# HSM_HSM_DTHE_CE000000h register map
Vendor: Texas Instruments
Peripheral module from a debugger description file (folder AM261x).
Registers are 32-bit, read-only, reset 0x0 unless marked. A register's access mark holds for its fields unless they carry their own. Offsets are as the file gives them; lines under a group give offsets from that group; [hi:lo] are bit positions; {n}, {i} and the like mark numbered series; 'fields as' and 'values as' point back to an identical list; <NAME> marks a mode.

## HSM_DTHE
0x00 HSM_DTHE_S_EIP_CONFIG 8-bit rw — This register is used for secured request configuration.
  [1:0] CONFIG — This register is secured request configuration.Writing 3 to this register enables the mreqsecure to enable the write to S_SYSCONFIG register in AES and SHA.
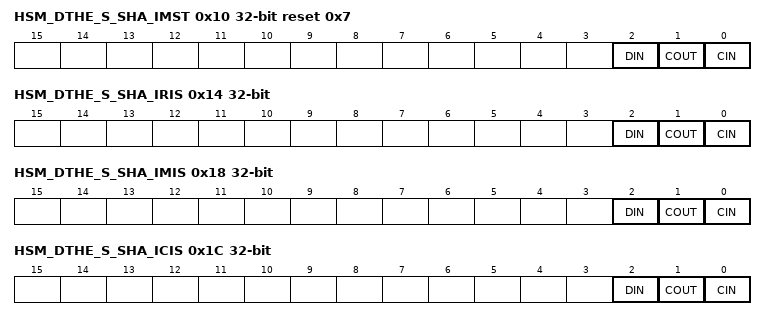
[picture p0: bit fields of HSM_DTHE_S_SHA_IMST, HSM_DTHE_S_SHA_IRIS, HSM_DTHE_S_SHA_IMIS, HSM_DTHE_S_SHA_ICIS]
0x10 HSM_DTHE_S_SHA_IMST rw reset 0x7 — Secured SHA Interrupt Mask Set Register.
  [2] DIN — Data in: this interrupt is raised when DMA writes last word of input data to internal FIFO of the engine
  [1] COUT — Context out: this interrupt is raised when DMA complets the output context movement from internal register
  [0] CIN — context in: this interrupt is raised when DMA complets Context write to internal register
0x14 HSM_DTHE_S_SHA_IRIS — Secured SHA Interrupt Raw Interrupt Status Register.
  [2] DIN — Input Data movement is done
  [1] COUT — Context output is done
  [0] CIN — context input is done
0x18 HSM_DTHE_S_SHA_IMIS — Secured SHA Interrupt Masked interrupt Status Registe.
  fields as HSM_DTHE_S_SHA_IRIS
0x1C HSM_DTHE_S_SHA_ICIS wo — Secured SHA Interrupt Clear Interrupt Status Register.
  [2] DIN — Clear'input Data movement done' flag
  [1] COUT — Clear'Context output done' flag
  [0] CIN — Clear'context input done' flag
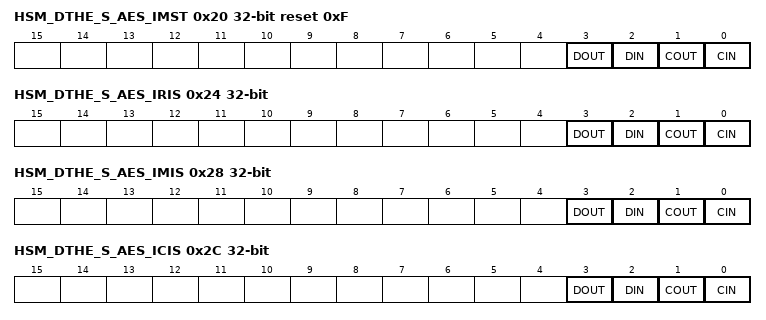
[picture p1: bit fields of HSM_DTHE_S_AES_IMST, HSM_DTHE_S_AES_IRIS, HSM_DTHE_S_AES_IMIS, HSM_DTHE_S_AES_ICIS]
0x20 HSM_DTHE_S_AES_IMST rw reset 0xF — Secured AES Interrupt Mask Set Register.
  [3] DOUT — Data out: this interrupt is raised when DMA finishes Writing last word of the process result
  [2] DIN — Data in: this interrupt is raised when DMA writes last word of input data to internal FIFO of the engine
  [1] COUT — Context out: this interrupt is raised when DMA complets the output context movement from internal register
  [0] CIN — context in: this interrupt is raised when DMA complets Context write to internal register
0x24 HSM_DTHE_S_AES_IRIS — Secured AES Interrupt Raw Interrupt Status Register.
  [3] DOUT — Output Data movement is done
  [2] DIN — Input Data movement is done
  [1] COUT — Context output is done
  [0] CIN — context input is done
0x28 HSM_DTHE_S_AES_IMIS — Secured AES Interrupt Masked interrupt Status Register.
  fields as HSM_DTHE_S_AES_IRIS
0x2C HSM_DTHE_S_AES_ICIS wo — Secured AES Interrupt Clear Interrupt Status Register.
  [3] DOUT — Clear'output Data movement done' flag
  [2] DIN — Clear'input Data movement done' flag
  [1] COUT — Clear'Context output done' flag
  [0] CIN — Clear'context input done' flag
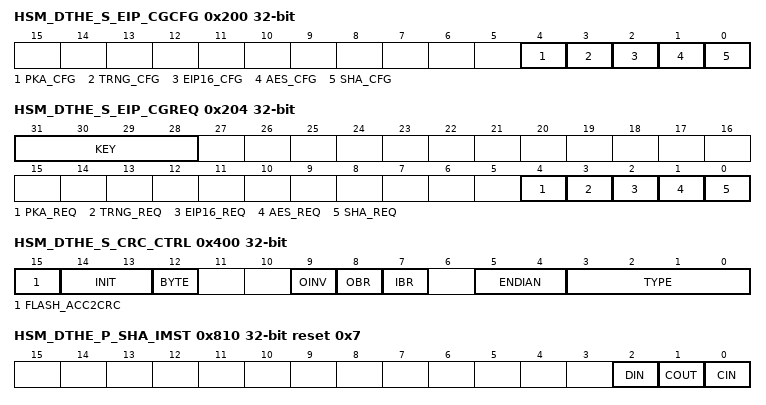
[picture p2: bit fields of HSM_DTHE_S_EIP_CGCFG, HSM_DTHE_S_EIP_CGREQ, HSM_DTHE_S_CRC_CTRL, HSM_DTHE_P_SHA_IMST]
0x200 HSM_DTHE_S_EIP_CGCFG wo — Secured EIP Clock gating configuration.
  [4] PKA_CFG — 0- request to un-gate 1- request to gate the clock.
  [3] TRNG_CFG — 0- request to un-gate 1- request to gate the clock.
  [2] EIP16_CFG — 0- request to un-gate 1- request to gate the clock.
  [1] AES_CFG — 0- request to un-gate 1- request to gate the clock.
  [0] SHA_CFG — 0- request to un-gate 1- request to gate the clock.
0x204 HSM_DTHE_S_EIP_CGREQ wo — Secured EIP Clock gating Request.
  [31:28] KEY — When'0x5' write'1' to lower bits [4:0] will set the bit. Write'0' will be ignoredWhen'0x2' write'1' to lower bit [4:0] will clear the bit. Write'0' will be ignoredfor other key value, regular read write operation
  [4] PKA_REQ — 0- request to un-gate 1- request to gate the clock.
  [3] TRNG_REQ — 0- request to un-gate 1- request to gate the clock.
  [2] EIP16_REQ — 0- request to un-gate 1- request to gate the clock.
  [1] AES_REQ — 0- request to un-gate 1- request to gate the clock.
  [0] SHA_REQ — 0- request to un-gate 1- request to gate the clock.
0x400 HSM_DTHE_S_CRC_CTRL rw — Secured CRC Control register.
  [15] FLASH_ACC2CRC — 1 if use Flash access port to feed CRC [uses length and address in that block to control data [Reserved]. Only present in DTHE_S_CRC_CTRL register
  [14:13] INIT — Initialize the CRC 00- use SEED register context as starting value 10- all'zero' 11- all'one' This is self clearing. With first write to data register this value clears to zero and remain zero for rest of the operation unless written again
  [12] BYTE — Input data size 0- 32 bit 1- 8 bit
  [9] OINV — Inverse the bits of result before storing to CRC_RSLT_PP0
  [8] OBR — Bit reserved the output result byte before storing to CRC_RSLT_PP0. applicable for all bytes in word
  [7] IBR — Bit reverse the input byte. For all bytes in word
  [5:4] ENDIAN — Endian control [0]- swap byte in half-word [1]- swap half word
  [3:0] TYPE — Type of operation0000 polynomial 0x8005 0001 polynomial 0x10210010 polynomial 0x4C11DB7 0011 polynomial 0x1EDC6F411000 TCP checksumTYPE in DTHE_S_CRC_CTRL & DTHE_S_CRC_CTRL should be exclusive
0x410 HSM_DTHE_S_CRC_SEED rw — SecuredCRC SEED/Context-CRC register.
  [31:0] SEED — Starting seed of CRC and checksum operation. Please see CTRL register for more detail. This resister also holds the latest result of CRC or checksum operation
0x414 HSM_DTHE_S_CRC_DIN rw — Secured CRC DATA Input register.
  [31:0] DATA_IN — Input data for CRC or checksum operation
0x418 HSM_DTHE_S_CRC_RSLT_PP — Secured CRC post processed output.
  [31:0] RSLT_PP — Result data of CRC or checksum operation
0x810 HSM_DTHE_P_SHA_IMST rw reset 0x7 — Public SHA Interrupt Mask Set Register.
  fields as HSM_DTHE_S_SHA_IMST
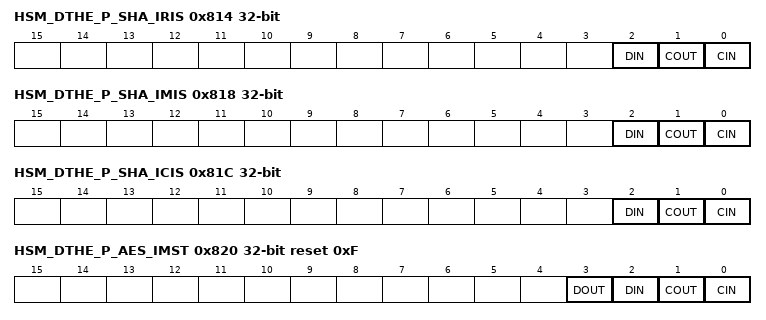
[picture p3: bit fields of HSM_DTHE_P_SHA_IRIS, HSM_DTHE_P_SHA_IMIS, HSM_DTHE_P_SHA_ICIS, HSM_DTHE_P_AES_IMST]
0x814 HSM_DTHE_P_SHA_IRIS — Public SHA Interrupt Raw Interrupt Status Register.
  fields as HSM_DTHE_S_SHA_IRIS
0x818 HSM_DTHE_P_SHA_IMIS — Public SHA Interrupt Masked interrupt Status Registe.
  fields as HSM_DTHE_S_SHA_IRIS
0x81C HSM_DTHE_P_SHA_ICIS wo — Public SHA Interrupt Clear Interrupt Status Register.
  fields as HSM_DTHE_S_SHA_ICIS
0x820 HSM_DTHE_P_AES_IMST rw reset 0xF — Public AES Interrupt Mask Set Register.
  fields as HSM_DTHE_S_AES_IMST
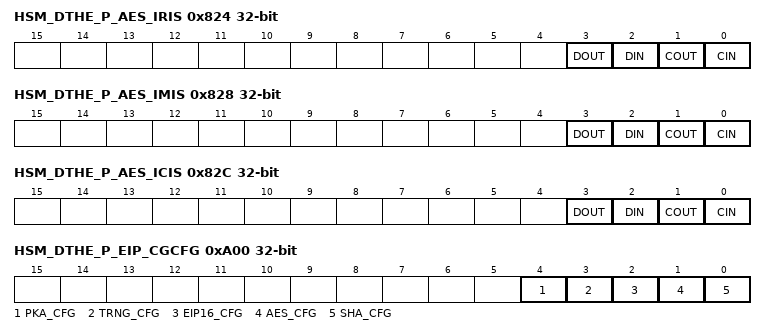
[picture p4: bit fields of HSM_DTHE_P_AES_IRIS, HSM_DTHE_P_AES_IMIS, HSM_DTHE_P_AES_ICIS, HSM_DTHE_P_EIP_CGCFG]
0x824 HSM_DTHE_P_AES_IRIS — Public AES Interrupt Raw Interrupt Status Register.
  fields as HSM_DTHE_S_AES_IRIS
0x828 HSM_DTHE_P_AES_IMIS — Public AES Interrupt Masked interrupt Status Register.
  fields as HSM_DTHE_S_AES_IRIS
0x82C HSM_DTHE_P_AES_ICIS access per field — Public AES Interrupt Clear Interrupt Status Register.
  [3] DOUT rw — Clear'output Data movement done' flag
  [2] DIN wo — Clear'input Data movement done' flag
  [1] COUT wo — Clear'Context output done' flag
  [0] CIN wo — Clear'context input done' flag
0xA00 HSM_DTHE_P_EIP_CGCFG wo — Public EIP Clock gating configuration.
  fields as HSM_DTHE_S_EIP_CGCFG
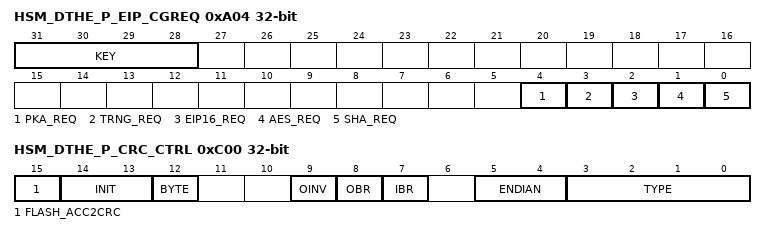
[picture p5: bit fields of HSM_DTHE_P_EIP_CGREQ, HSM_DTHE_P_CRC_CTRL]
0xA04 HSM_DTHE_P_EIP_CGREQ wo — Public EIP Clock gating Request.
  fields as HSM_DTHE_S_EIP_CGREQ
0xC00 HSM_DTHE_P_CRC_CTRL rw — Public CRC Control register.
  fields as HSM_DTHE_S_CRC_CTRL
0xC10 HSM_DTHE_P_CRC_SEED rw — PublicCRC SEED/Context-CRC register.
  fields as HSM_DTHE_S_CRC_SEED
0xC14 HSM_DTHE_P_CRC_DIN rw — Public CRC DATA Input register.
  [31:0] DATA_IN — Input data for CRC or checksum operation
0xC18 HSM_DTHE_P_CRC_RSLT_PP — Public CRC post processed output.
  [31:0] RSLT_PP — Result data of CRC or checksum operation
{0xF00+4i} HSM_DTHE_P_RAND_KEY{i} (i=0..3) — Device Specific Randon key [{32i+31}:{32i}].
  [31:0] KEY{32i+31}_{32i} — Device Specific Randon key [{32i+31}:{32i}]
